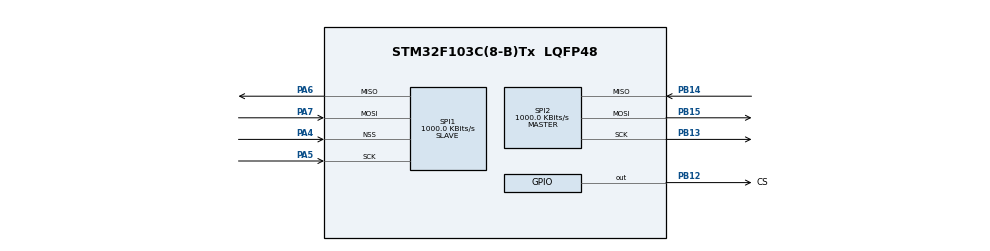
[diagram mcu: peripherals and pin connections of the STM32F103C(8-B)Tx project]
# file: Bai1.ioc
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Dma.Request0=SPI1_RX
Dma.SPI1_RX.0.Direction=DMA_PERIPH_TO_MEMORY
Dma.SPI1_RX.0.Instance=DMA1_Channel2
Dma.SPI1_RX.0.MemDataAlignment=DMA_MDATAALIGN_BYTE
Dma.SPI1_RX.0.MemInc=DMA_MINC_ENABLE
Dma.SPI1_RX.0.Mode=DMA_NORMAL
Dma.SPI1_RX.0.PeriphDataAlignment=DMA_PDATAALIGN_BYTE
Dma.SPI1_RX.0.PeriphInc=DMA_PINC_DISABLE
Dma.SPI1_RX.0.Priority=DMA_PRIORITY_LOW
Mcu.Family=STM32F1
Mcu.Name=STM32F103C(8-B)Tx
Mcu.Package=LQFP48
NVIC.DMA1_Channel2_IRQn=true\:0\:0\:false\:false\:true\:false\:true
NVIC.PriorityGroup=NVIC_PRIORITYGROUP_4
NVIC.SPI1_IRQn=true\:0\:0\:false\:false\:true\:true\:true
NVIC.SPI2_IRQn=true\:0\:0\:false\:false\:true\:true\:true
PA13.Mode=Serial_Wire
PA13.Signal=SYS_JTMS-SWDIO
PA14.Mode=Serial_Wire
PA14.Signal=SYS_JTCK-SWCLK
PA4.Mode=NSS_Signal_Hard_Input
PA4.Signal=SPI1_NSS
PA5.Mode=Full_Duplex_Slave
PA5.Signal=SPI1_SCK
PA6.Mode=Full_Duplex_Slave
PA6.Signal=SPI1_MISO
PA7.Mode=Full_Duplex_Slave
PA7.Signal=SPI1_MOSI
PB12.GPIO_Label=CS
PB12.Signal=GPIO_Output
PB13.Mode=Full_Duplex_Master
PB13.Signal=SPI2_SCK
PB14.Mode=Full_Duplex_Master
PB14.Signal=SPI2_MISO
PB15.Mode=Full_Duplex_Master
PB15.Signal=SPI2_MOSI
ProjectManager.HeapSize=0x200
ProjectManager.StackSize=0x400
ProjectManager.TargetToolchain=MDK-ARM V5.27
RCC.APB1Freq_Value=8000000
RCC.APB2Freq_Value=8000000
SPI1.BaudRatePrescaler=SPI_BAUDRATEPRESCALER_8
SPI1.CalculateBaudRate=1000.0 KBits/s
SPI1.Direction=SPI_DIRECTION_2LINES
SPI1.Mode=SPI_MODE_SLAVE
SPI1.VirtualNSS=VM_NSSHARD
SPI1.VirtualType=VM_SLAVE
SPI2.BaudRatePrescaler=SPI_BAUDRATEPRESCALER_8
SPI2.CalculateBaudRate=1000.0 KBits/s
SPI2.Direction=SPI_DIRECTION_2LINES
SPI2.Mode=SPI_MODE_MASTER
SPI2.VirtualType=VM_MASTER
board=custom

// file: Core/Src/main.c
/* USER CODE BEGIN Header */
/**
  ******************************************************************************
  * @file           : main.c
  * @brief          : Main program body
  ******************************************************************************
  * @attention
  *
  * <h2><center>&copy; Copyright (c) 2021 STMicroelectronics.
  * All rights reserved.</center></h2>
  *
  * This software component is licensed by ST under BSD 3-Clause license,
  * the "License"; You may not use this file except in compliance with the
  * License. You may obtain a copy of the License at:
  *                        opensource.org/licenses/BSD-3-Clause
  *
  ******************************************************************************
  */
/* USER CODE END Header */
#include "main.h"
#include "stdio.h"

/* USER CODE BEGIN Includes */
#define sizeofBuff 20
uint8_t u8_SPI2_TxBuff[sizeofBuff] = "Master send";
uint8_t u8_SPI1_RxBuff[sizeofBuff];
uint8_t Count;
/* USER CODE END Includes */

SPI_HandleTypeDef hspi1;
SPI_HandleTypeDef hspi2;
DMA_HandleTypeDef hdma_spi1_rx;

void SystemClock_Config(void);
static void MX_GPIO_Init(void);
static void MX_DMA_Init(void);
static void MX_SPI1_Init(void);
static void MX_SPI2_Init(void);

int main(void)
{

  /* MCU Configuration--------------------------------------------------------*/

  /* Reset of all peripherals, Initializes the Flash interface and the Systick. */
  HAL_Init();

  /* Configure the system clock */
  SystemClock_Config();

  /* Initialize all configured peripherals */
  MX_GPIO_Init();
  MX_DMA_Init();
  MX_SPI1_Init();
  MX_SPI2_Init();
  /* USER CODE BEGIN 2 */
	HAL_SPI_Receive_DMA(&hspi1,u8_SPI1_RxBuff,sizeofBuff);
	HAL_SPI_Transmit(&hspi2,u8_SPI2_TxBuff,sizeofBuff,100);

  /* USER CODE END 2 */

  /* Infinite loop */
  while (1)
  {
		sprintf((char*)u8_SPI2_TxBuff,"Gui lan thu: %d \n", Count);
		HAL_GPIO_WritePin(CS_GPIO_Port, CS_Pin, GPIO_PIN_RESET);
		HAL_SPI_Transmit(&hspi2,u8_SPI2_TxBuff,sizeofBuff,100);
		HAL_GPIO_WritePin(CS_GPIO_Port, CS_Pin, GPIO_PIN_SET);
		Count++;
		HAL_Delay(1000);
  }
}

void SystemClock_Config(void)
{
  RCC_OscInitTypeDef RCC_OscInitStruct = {0};
  RCC_ClkInitTypeDef RCC_ClkInitStruct = {0};

  /** Initializes the RCC Oscillators according to the specified parameters
  * in the RCC_OscInitTypeDef structure.
  */
  RCC_OscInitStruct.OscillatorType = RCC_OSCILLATORTYPE_HSI;
  RCC_OscInitStruct.HSIState = RCC_HSI_ON;
  RCC_OscInitStruct.HSICalibrationValue = RCC_HSICALIBRATION_DEFAULT;
  RCC_OscInitStruct.PLL.PLLState = RCC_PLL_NONE;
  if (HAL_RCC_OscConfig(&RCC_OscInitStruct) != HAL_OK)
  {
    Error_Handler();
  }
  /** Initializes the CPU, AHB and APB buses clocks
  */
  RCC_ClkInitStruct.ClockType = RCC_CLOCKTYPE_HCLK|RCC_CLOCKTYPE_SYSCLK
                              |RCC_CLOCKTYPE_PCLK1|RCC_CLOCKTYPE_PCLK2;
  RCC_ClkInitStruct.SYSCLKSource = RCC_SYSCLKSOURCE_HSI;
  RCC_ClkInitStruct.AHBCLKDivider = RCC_SYSCLK_DIV1;
  RCC_ClkInitStruct.APB1CLKDivider = RCC_HCLK_DIV1;
  RCC_ClkInitStruct.APB2CLKDivider = RCC_HCLK_DIV1;

  if (HAL_RCC_ClockConfig(&RCC_ClkInitStruct, FLASH_LATENCY_0) != HAL_OK)
  {
    Error_Handler();
  }
}

static void MX_SPI1_Init(void)
{

  /* SPI1 parameter configuration*/
  hspi1.Instance = SPI1;
  hspi1.Init.Mode = SPI_MODE_SLAVE;
  hspi1.Init.Direction = SPI_DIRECTION_2LINES;
  hspi1.Init.DataSize = SPI_DATASIZE_8BIT;
  hspi1.Init.CLKPolarity = SPI_POLARITY_LOW;
  hspi1.Init.CLKPhase = SPI_PHASE_1EDGE;
  hspi1.Init.NSS = SPI_NSS_HARD_INPUT;
  hspi1.Init.BaudRatePrescaler = SPI_BAUDRATEPRESCALER_8;
  hspi1.Init.FirstBit = SPI_FIRSTBIT_MSB;
  hspi1.Init.TIMode = SPI_TIMODE_DISABLE;
  hspi1.Init.CRCCalculation = SPI_CRCCALCULATION_DISABLE;
  hspi1.Init.CRCPolynomial = 10;
  if (HAL_SPI_Init(&hspi1) != HAL_OK)
  {
    Error_Handler();
  }

}

static void MX_SPI2_Init(void)
{

  /* SPI2 parameter configuration*/
  hspi2.Instance = SPI2;
  hspi2.Init.Mode = SPI_MODE_MASTER;
  hspi2.Init.Direction = SPI_DIRECTION_2LINES;
  hspi2.Init.DataSize = SPI_DATASIZE_8BIT;
  hspi2.Init.CLKPolarity = SPI_POLARITY_LOW;
  hspi2.Init.CLKPhase = SPI_PHASE_1EDGE;
  hspi2.Init.NSS = SPI_NSS_SOFT;
  hspi2.Init.BaudRatePrescaler = SPI_BAUDRATEPRESCALER_8;
  hspi2.Init.FirstBit = SPI_FIRSTBIT_MSB;
  hspi2.Init.TIMode = SPI_TIMODE_DISABLE;
  hspi2.Init.CRCCalculation = SPI_CRCCALCULATION_DISABLE;
  hspi2.Init.CRCPolynomial = 10;
  if (HAL_SPI_Init(&hspi2) != HAL_OK)
  {
    Error_Handler();
  }

}

static void MX_DMA_Init(void)
{

  /* DMA controller clock enable */
  __HAL_RCC_DMA1_CLK_ENABLE();

  /* DMA interrupt init */
  /* DMA1_Channel2_IRQn interrupt configuration */
  HAL_NVIC_SetPriority(DMA1_Channel2_IRQn, 0, 0);
  HAL_NVIC_EnableIRQ(DMA1_Channel2_IRQn);

}

static void MX_GPIO_Init(void)
{
  GPIO_InitTypeDef GPIO_InitStruct = {0};

  /* GPIO Ports Clock Enable */
  __HAL_RCC_GPIOA_CLK_ENABLE();
  __HAL_RCC_GPIOB_CLK_ENABLE();

  /*Configure GPIO pin Output Level */
  HAL_GPIO_WritePin(CS_GPIO_Port, CS_Pin, GPIO_PIN_RESET);

  /*Configure GPIO pin : CS_Pin */
  GPIO_InitStruct.Pin = CS_Pin;
  GPIO_InitStruct.Mode = GPIO_MODE_OUTPUT_PP;
  GPIO_InitStruct.Pull = GPIO_NOPULL;
  GPIO_InitStruct.Speed = GPIO_SPEED_FREQ_LOW;
  HAL_GPIO_Init(CS_GPIO_Port, &GPIO_InitStruct);

}

void Error_Handler(void)
{
  __disable_irq();
  while (1)
  {
  }
}

/************************ (C) COPYRIGHT STMicroelectronics *****END OF FILE****/
